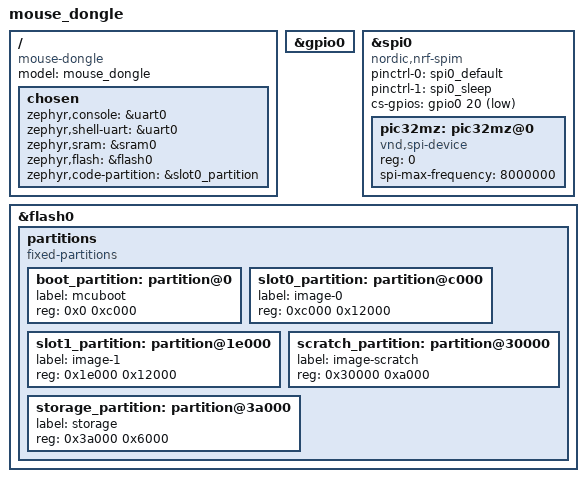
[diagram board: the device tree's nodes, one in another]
// Copyright (c) 2022 Nordic Semiconductor ASA
// SPDX-License-Identifier: Apache-2.0

/dts-v1/;
#include <nordic/nrf52820_qdaa.dtsi>
#include "mouse_dongle-pinctrl.dtsi"

/ {
	model = "mouse_dongle";
	compatible = "mouse-dongle";

	chosen {
		zephyr,console = &uart0;
		zephyr,shell-uart = &uart0;
		zephyr,sram = &sram0;
		zephyr,flash = &flash0;
		zephyr,code-partition = &slot0_partition;
	};
};

&gpio0 {
	status = "okay";
};

&spi0 {
	compatible = "nordic,nrf-spim";
	status = "okay";
	pinctrl-0 = <&spi0_default>;
	pinctrl-1 = <&spi0_sleep>;
	pinctrl-names = "default", "sleep";
	cs-gpios = <&gpio0 20 GPIO_ACTIVE_LOW>;
	pic32mz: pic32mz@0 {
		compatible = "vnd,spi-device";
		reg = <0>;
		spi-max-frequency = <8000000>;
	};
};	


&flash0 {
	partitions {
		compatible = "fixed-partitions";
		#address-cells = <1>;
		#size-cells = <1>;

		boot_partition: partition@0 {
			label = "mcuboot";
			reg = <0x0 0xc000>;
		};
		slot0_partition: partition@c000 {
			label = "image-0";
			reg = <0xc000 0x12000>;
		};
		slot1_partition: partition@1e000 {
			label = "image-1";
			reg = <0x1e000 0x12000>;
		};
		scratch_partition: partition@30000 {
			label = "image-scratch";
			reg = <0x30000 0xa000>;
		};
		storage_partition: partition@3a000 {
			label = "storage";
			reg = <0x3a000 0x6000>;
		};
	};
};

